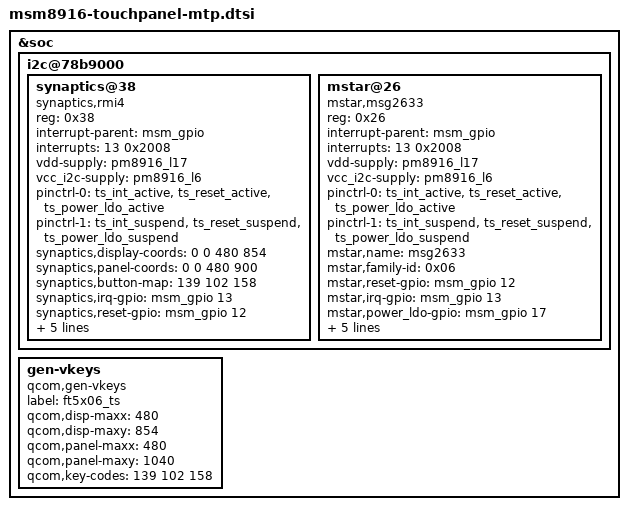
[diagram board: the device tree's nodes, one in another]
/* Copyright (c) 2013-2014, The Linux Foundation. All rights reserved.
 *
 * This program is free software; you can redistribute it and/or modify
 * it under the terms of the GNU General Public License version 2 and
 * only version 2 as published by the Free Software Foundation.
 *
 * This program is distributed in the hope that it will be useful,
 * but WITHOUT ANY WARRANTY; without even the implied warranty of
 * MERCHANTABILITY or FITNESS FOR A PARTICULAR PURPOSE.  See the
 * GNU General Public License for more details.
 */

&soc {
	i2c@78b9000 { /* BLSP1 QUP5 */
                synaptics@38 {
                        compatible = "synaptics,rmi4";
                        reg = <0x38>;
                        interrupt-parent = <&msm_gpio>;
                        interrupts = <13 0x2008>;
                        vdd-supply = <&pm8916_l17>;
                        vcc_i2c-supply = <&pm8916_l6>;
                        /* pins used by touchscreen */
                        pinctrl-names = "pmx_ts_active","pmx_ts_suspend";
                        pinctrl-0 = <&ts_int_active &ts_reset_active &ts_power_ldo_active>;
                        pinctrl-1 = <&ts_int_suspend &ts_reset_suspend &ts_power_ldo_suspend>;
                        synaptics,display-coords = <0 0 480 854>;
                        synaptics,panel-coords = <0 0 480 900>;
                        synaptics,button-map= <139 102 158>;
                        synaptics,irq-gpio = <&msm_gpio 13 0x2008>;
                        synaptics,reset-gpio = <&msm_gpio 12 0x0>;
			synaptics,power_ldo-gpio = <&msm_gpio 78 0x0>;
			synaptics,fw-image-name = "synaptics_dsx_fw_update.bin";
                        synaptics,i2c-pull-up;
                        synaptics,power-down;
                };

		/*mstar msg2633 tp*/
		mstar@26{
			compatible = "mstar,msg2633";
			reg = <0x26>;
			interrupt-parent = <&msm_gpio>;
			interrupts = <13 0x2008>;
			vdd-supply = <&pm8916_l17>;
			vcc_i2c-supply = <&pm8916_l6>;
			pinctrl-names = "pmx_ts_active","pmx_ts_suspend";
			pinctrl-0 = <&ts_int_active &ts_reset_active &ts_power_ldo_active>;
			pinctrl-1 = <&ts_int_suspend &ts_reset_suspend &ts_power_ldo_suspend>;
			mstar,name = "msg2633";
			mstar,family-id = <0x06>;
			mstar,reset-gpio = <&msm_gpio 12 0x00>;
			mstar,irq-gpio = <&msm_gpio 13 0x2008>;
			mstar,power_ldo-gpio = <&msm_gpio 17 0x0>;
			mstar,display-coords = <0 0 480 800>;
			mstar,panel-coords = <0 0 480 850>;
			mstar,button-map= <158 102 139>;
			mstar,no-force-update;
			mstar,i2c-pull-up;
		};
	};

	gen-vkeys {
		compatible = "qcom,gen-vkeys";
	label = "ft5x06_ts";
	qcom,disp-maxx = <480>;
	qcom,disp-maxy = <854>;
	qcom,panel-maxx = <480>;
	qcom,panel-maxy = <1040>;
	qcom,key-codes = <139 102 158>;
	};
};

